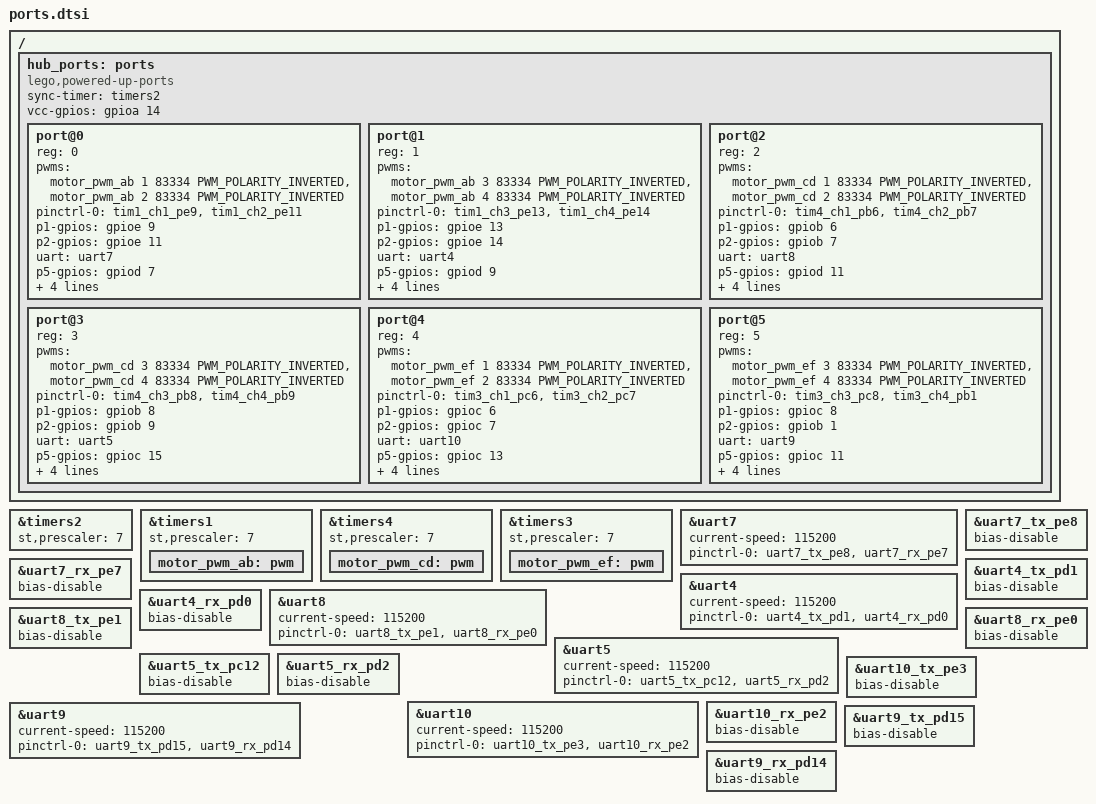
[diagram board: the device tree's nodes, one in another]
// SPDX-License-Identifier: MIT
// Copyright (c) 2018-2025 The Pybricks Authors
/* Prime F4 port wiring from platform/prime_hub_f4/platform.c at a7b1b04ae. */
/ {
	hub_ports: ports {
		compatible = "lego,powered-up-ports";
		sync-timer = <&timers2>;
		vcc-gpios = <&gpioa 14 GPIO_ACTIVE_HIGH>;
		#address-cells = <1>;
		#size-cells = <0>;
		port@0 {
			reg = <0>;
			pwms = <&motor_pwm_ab 1 83334 PWM_POLARITY_INVERTED>, <&motor_pwm_ab 2 83334 PWM_POLARITY_INVERTED>;
			pinctrl-0 = <&tim1_ch1_pe9 &tim1_ch2_pe11>;
			pinctrl-names = "default";
			p1-gpios = <&gpioe 9 GPIO_ACTIVE_HIGH>;
			p2-gpios = <&gpioe 11 GPIO_ACTIVE_HIGH>;
			uart = <&uart7>;
			p5-gpios = <&gpiod 7 GPIO_ACTIVE_HIGH>;
			p6-gpios = <&gpiod 8 GPIO_ACTIVE_HIGH>;
			tx-gpios = <&gpioe 8 GPIO_ACTIVE_HIGH>;
			rx-gpios = <&gpioe 7 GPIO_ACTIVE_HIGH>;
			buffer-gpios = <&gpioa 10 GPIO_ACTIVE_LOW>;
		};
		port@1 {
			reg = <1>;
			pwms = <&motor_pwm_ab 3 83334 PWM_POLARITY_INVERTED>, <&motor_pwm_ab 4 83334 PWM_POLARITY_INVERTED>;
			pinctrl-0 = <&tim1_ch3_pe13 &tim1_ch4_pe14>;
			pinctrl-names = "default";
			p1-gpios = <&gpioe 13 GPIO_ACTIVE_HIGH>;
			p2-gpios = <&gpioe 14 GPIO_ACTIVE_HIGH>;
			uart = <&uart4>;
			p5-gpios = <&gpiod 9 GPIO_ACTIVE_HIGH>;
			p6-gpios = <&gpiod 10 GPIO_ACTIVE_HIGH>;
			tx-gpios = <&gpiod 1 GPIO_ACTIVE_HIGH>;
			rx-gpios = <&gpiod 0 GPIO_ACTIVE_HIGH>;
			buffer-gpios = <&gpioa 8 GPIO_ACTIVE_LOW>;
		};
		port@2 {
			reg = <2>;
			pwms = <&motor_pwm_cd 1 83334 PWM_POLARITY_INVERTED>, <&motor_pwm_cd 2 83334 PWM_POLARITY_INVERTED>;
			pinctrl-0 = <&tim4_ch1_pb6 &tim4_ch2_pb7>;
			pinctrl-names = "default";
			p1-gpios = <&gpiob 6 GPIO_ACTIVE_HIGH>;
			p2-gpios = <&gpiob 7 GPIO_ACTIVE_HIGH>;
			uart = <&uart8>;
			p5-gpios = <&gpiod 11 GPIO_ACTIVE_HIGH>;
			p6-gpios = <&gpioe 4 GPIO_ACTIVE_HIGH>;
			tx-gpios = <&gpioe 1 GPIO_ACTIVE_HIGH>;
			rx-gpios = <&gpioe 0 GPIO_ACTIVE_HIGH>;
			buffer-gpios = <&gpioe 5 GPIO_ACTIVE_LOW>;
		};
		port@3 {
			reg = <3>;
			pwms = <&motor_pwm_cd 3 83334 PWM_POLARITY_INVERTED>, <&motor_pwm_cd 4 83334 PWM_POLARITY_INVERTED>;
			pinctrl-0 = <&tim4_ch3_pb8 &tim4_ch4_pb9>;
			pinctrl-names = "default";
			p1-gpios = <&gpiob 8 GPIO_ACTIVE_HIGH>;
			p2-gpios = <&gpiob 9 GPIO_ACTIVE_HIGH>;
			uart = <&uart5>;
			p5-gpios = <&gpioc 15 GPIO_ACTIVE_HIGH>;
			p6-gpios = <&gpioc 14 GPIO_ACTIVE_HIGH>;
			tx-gpios = <&gpioc 12 GPIO_ACTIVE_HIGH>;
			rx-gpios = <&gpiod 2 GPIO_ACTIVE_HIGH>;
			buffer-gpios = <&gpiob 2 GPIO_ACTIVE_LOW>;
		};
		port@4 {
			reg = <4>;
			pwms = <&motor_pwm_ef 1 83334 PWM_POLARITY_INVERTED>, <&motor_pwm_ef 2 83334 PWM_POLARITY_INVERTED>;
			pinctrl-0 = <&tim3_ch1_pc6 &tim3_ch2_pc7>;
			pinctrl-names = "default";
			p1-gpios = <&gpioc 6 GPIO_ACTIVE_HIGH>;
			p2-gpios = <&gpioc 7 GPIO_ACTIVE_HIGH>;
			uart = <&uart10>;
			p5-gpios = <&gpioc 13 GPIO_ACTIVE_HIGH>;
			p6-gpios = <&gpioe 12 GPIO_ACTIVE_HIGH>;
			tx-gpios = <&gpioe 3 GPIO_ACTIVE_HIGH>;
			rx-gpios = <&gpioe 2 GPIO_ACTIVE_HIGH>;
			buffer-gpios = <&gpiob 5 GPIO_ACTIVE_LOW>;
		};
		port@5 {
			reg = <5>;
			pwms = <&motor_pwm_ef 3 83334 PWM_POLARITY_INVERTED>, <&motor_pwm_ef 4 83334 PWM_POLARITY_INVERTED>;
			pinctrl-0 = <&tim3_ch3_pc8 &tim3_ch4_pb1>;
			pinctrl-names = "default";
			p1-gpios = <&gpioc 8 GPIO_ACTIVE_HIGH>;
			p2-gpios = <&gpiob 1 GPIO_ACTIVE_HIGH>;
			uart = <&uart9>;
			p5-gpios = <&gpioc 11 GPIO_ACTIVE_HIGH>;
			p6-gpios = <&gpioe 6 GPIO_ACTIVE_HIGH>;
			tx-gpios = <&gpiod 15 GPIO_ACTIVE_HIGH>;
			rx-gpios = <&gpiod 14 GPIO_ACTIVE_HIGH>;
			buffer-gpios = <&gpioc 5 GPIO_ACTIVE_LOW>;
		};
	};
};

/* These timers are owned exclusively by the port output adapter. PWM child
 * nodes retain channel/period wiring for pwms above, but instantiate no driver.
 * Both H-bridge legs remain muxed to preloaded compare outputs after coast init.
 * TIM2 supplies the common 12 kHz reset/update edge for TIM1, TIM4 and TIM3. */
&timers2 {
	status = "okay";
	st,prescaler = <7>;
};
&timers1 {
	status = "okay";
	st,prescaler = <7>;
	motor_pwm_ab: pwm {};
};
&timers4 {
	status = "okay";
	st,prescaler = <7>;
	motor_pwm_cd: pwm {};
};
&timers3 {
	status = "okay";
	st,prescaler = <7>;
	motor_pwm_ef: pwm {};
};

&uart7 {
	status = "okay";
	current-speed = <115200>;
	pinctrl-0 = <&uart7_tx_pe8 &uart7_rx_pe7>;
	pinctrl-names = "default";
};

&uart7_tx_pe8 {
	/delete-property/ bias-pull-up;
	bias-disable;
};

&uart7_rx_pe7 {
	/delete-property/ bias-pull-up;
	bias-disable;
};

&uart4 {
	status = "okay";
	current-speed = <115200>;
	pinctrl-0 = <&uart4_tx_pd1 &uart4_rx_pd0>;
	pinctrl-names = "default";
};

&uart4_tx_pd1 {
	/delete-property/ bias-pull-up;
	bias-disable;
};

&uart4_rx_pd0 {
	/delete-property/ bias-pull-up;
	bias-disable;
};

&uart8 {
	status = "okay";
	current-speed = <115200>;
	pinctrl-0 = <&uart8_tx_pe1 &uart8_rx_pe0>;
	pinctrl-names = "default";
};

&uart8_tx_pe1 {
	/delete-property/ bias-pull-up;
	bias-disable;
};

&uart8_rx_pe0 {
	/delete-property/ bias-pull-up;
	bias-disable;
};

&uart5 {
	status = "okay";
	current-speed = <115200>;
	pinctrl-0 = <&uart5_tx_pc12 &uart5_rx_pd2>;
	pinctrl-names = "default";
};

&uart5_tx_pc12 {
	/delete-property/ bias-pull-up;
	bias-disable;
};

&uart5_rx_pd2 {
	/delete-property/ bias-pull-up;
	bias-disable;
};

&uart10 {
	status = "okay";
	current-speed = <115200>;
	pinctrl-0 = <&uart10_tx_pe3 &uart10_rx_pe2>;
	pinctrl-names = "default";
};

&uart10_tx_pe3 {
	/delete-property/ bias-pull-up;
	bias-disable;
};

&uart10_rx_pe2 {
	/delete-property/ bias-pull-up;
	bias-disable;
};

&uart9 {
	status = "okay";
	current-speed = <115200>;
	pinctrl-0 = <&uart9_tx_pd15 &uart9_rx_pd14>;
	pinctrl-names = "default";
};

&uart9_tx_pd15 {
	/delete-property/ bias-pull-up;
	bias-disable;
};

&uart9_rx_pd14 {
	/delete-property/ bias-pull-up;
	bias-disable;
};
